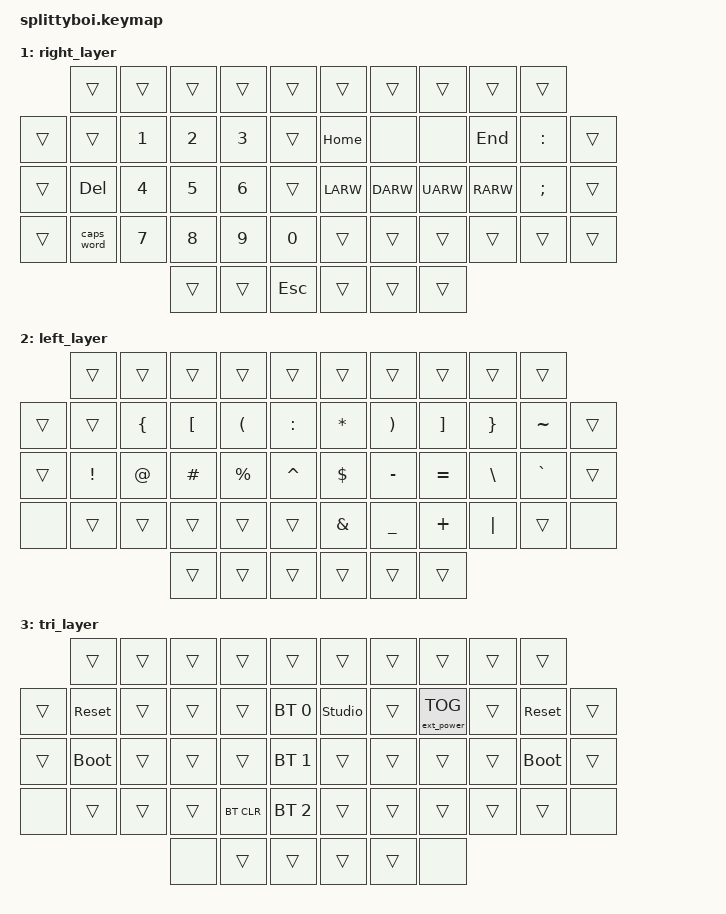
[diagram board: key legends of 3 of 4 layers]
// Copyright (c) 2022 The ZMK Contributors
// SPDX-License-Identifier: MIT

#include <behaviors.dtsi>
#include <dt-bindings/zmk/keys.h>
#include <dt-bindings/zmk/bt.h>
#include <dt-bindings/zmk/ext_power.h>

// Home row mods macro
#define HRML(k2,k3,k4) &ht LCTRL k2  &ht LALT k3  &ht LGUI k4
#define HRMR(k1,k2,k3) &ht RGUI k1  &ht RALT k2  &ht RCTRL k3

/ {
    behaviors {
        ht: hold_tap {
            label = "hold_tap";
            compatible = "zmk,behavior-hold-tap";
            #binding-cells = <2>;
            flavor = "tap-preferred";
            tapping-term-ms = <220>;
            quick-tap-ms = <150>;
            global-quick-tap;
            bindings = <&kp>, <&kp>;
        };    
    };

    macros {
        ZMK_MACRO(nvim_save,
            wait-ms = <10>;
            tap-ms = <20>;
            bindings = <&kp COLON  &kp W &kp ENTER>;
        )
    
        ZMK_MACRO(quit_nvim,
            wait-ms = <10>;
            tap-ms = <20>;
            bindings = <&kp COLON  &kp Q &kp ENTER>;
        )
        tmux_prefix: tmux_prefix {
            compatible = "zmk,behavior-macro";
            #binding-cells = <0>;
            bindings
                = <&macro_press &kp LCTRL>
                , <&macro_tap &kp A>
                , <&macro_release &kp LCTRL>
                ;
        };
    };

    conditional_layers {
        compatible = "zmk,conditional-layers";
        tri_layer {
            if-layers = <1 2>;
            then-layer = <3>;
        };
    };


    keymap {
        compatible = "zmk,keymap";
        default_layer {
            bindings = <
        //              ╭──────────┬──────────┬──────────┬──────────┬──────────╮   ╭──────────┬──────────┬──────────┬──────────┬──────────╮
        //              │  1       │  2       │  3       │  4       │     5    │   │  6       │  7       │  8       │  9       │   0      │
                            &kp N1   &kp N2     &kp N3       &kp N4     &kp N5      &kp N6  &kp N7      &kp N8   &kp N9     &kp N0 
        //   ╭──────────┼──────────┼──────────┼──────────┼──────────┼──────────┤   ├──────────┼──────────┼──────────┼──────────┼──────────┼──────────╮
        //   │          │  Q       │  W       │  E       │  R       │  T       │   │  Y       │  U       │  I       │  O       │  P       │          │
               &none       &kp Q      &kp W      &kp E      &kp R      &kp T          &kp Y      &kp U      &kp I      &kp O      &kp P     &none    
        //   ├──────────┼──────────┼──────────┼──────────┼──────────┼──────────┤   ├──────────┼──────────┼──────────┼──────────┼──────────┼──────────┤
        //   │  SHIFT   │  A       │  S       │  D       │  F       │  G       │   │  H       │  J       │  K       │  L       │ ' "      │  SHIFT   │
              &kp LSHFT   &kp A    HRML( S,         D,         F)     &kp G          &kp H      HRMR(J,        K,         L)     &kp SQT   &kp RSHFT
        //   ├──────────┼──────────┼──────────┼──────────┼──────────┼──────────┤   ├──────────┼──────────┼──────────┼──────────┼──────────┼──────────┤
        //   │          │  Z       │  X       │  C       │  V       │  B       │   │  N       │  M       │ , <      │ . >      │ / ?      │          │ 
               &none      &kp Z      &kp X      &kp C      &kp V      &kp B          &kp N      &kp M      &kp COMMA  &kp DOT    &kp FSLH   &none   
        //   ╰──────────┴──────────┴──────────┼──────────┼──────────┼──────────┤   ├──────────┼──────────┼──────────┼──────────┴──────────┴──────────╯
                                                &mo 2      &kp TAB   &kp ENTER      &kp BSPC    &none     &lt 1 SPACE  
        //                                    ╰──────────┴──────────┴──────────╯   ╰──────────┴──────────┴──────────╯
            >;
        };


        right_layer {
            bindings = <
        //           ╭──────────┬──────────┬──────────┬──────────┬──────────╮   ╭──────────┬──────────┬──────────┬──────────┬──────────╮
        //           │  0       │  1       │  2       │  3       │  4       │   │  5       │  6       │  7       │  8       │  9       │
                       &trans     &trans     &trans    &trans      &trans        &trans      &trans      &trans      &trans      &trans
        //╭──────────┼──────────┼──────────┼──────────┼──────────┼──────────┤   ├──────────┼──────────┼──────────┼──────────┼──────────┼──────────╮
        //│          │    Q     │  1       │  2       │  3       │          │   │ HOME     | none     | none     │ END      │  :       │          │
            &trans     &trans    &kp N1     &kp N2     &kp N3     &trans         &kp HOME   &none     &none       &kp END    &kp COLON   &trans  
        //├──────────┼──────────┼──────────┼──────────┼──────────┼──────────┤   ├──────────┼──────────┼──────────┼──────────┼──────────┼──────────┤
        //│  SHIFT   │ DELETE   │  4       │  5       │  6       │          │   │ LEFT     │ DOWN     │ UP       │ RIGHT    │  ;       │  SHIFT   │
           &trans     &kp DEL    &kp N4     &kp N5     &kp N6     &trans         &kp LARW   &kp DARW   &kp UARW    &kp RARW   &kp SEMI   &trans
        //├──────────┼──────────┼──────────┼──────────┼──────────┼──────────┤   ├──────────┼──────────┼──────────┼──────────┼──────────┼──────────┤
        //│          │ CAPS     │  7       │  8       │  9       │  0       │   │          │          │          │          │          │          │
            &trans    &caps_word  &kp N7     &kp N8     &kp N9     &kp N0         &trans     &trans     &trans     &trans     &trans      &trans   
        //╰──────────┴──────────┴──────────┴──────────┼──────────┼──────────┤   ├──────────┼──────────┼──────────┴──────────┴──────────┴──────────╯
                                               &trans   &trans      &kp ESC         &trans     &trans     &trans
        //                                 ╰──────────┴──────────┴──────────╯   ╰──────────┴──────────┴──────────╯
            >;
        };

        left_layer {
            bindings = <
        //           ╭──────────┬──────────┬──────────┬──────────┬──────────╮   ╭──────────┬──────────┬──────────┬──────────┬──────────╮
        //           │  0       │  1       │  2       │  3       │  4       │   │  5       │  6       │  7       │  8       │  9       │
                       &trans     &trans     &trans    &trans      &trans        &trans      &trans      &trans      &trans      &trans
        //╭──────────┼──────────┼──────────┼──────────┼──────────┼──────────┤   ├──────────┼──────────┼──────────┼──────────┼──────────┼──────────╮
        //│          │          │ {        │  [       │  (       │    :     │   │   *      │  )       │  ]       │  }       │  ~       │          │
            &trans    &trans     &kp LBRC   &kp LBKT   &kp LPAR   &kp COLON      &kp ASTRK &kp RPAR   &kp RBKT   &kp RBRC   &kp TILDE     &trans
        //├──────────┼──────────┼──────────┼──────────┼──────────┼──────────┤   ├──────────┼──────────┼──────────┼──────────┼──────────┼──────────╮
        //│  SHIFT   │  !       │  @       │  #       │   %      │    ^     │   │   $      │  -       │  =       │  \       │  `       │  SHIFT   │
           &trans     &kp EXCL   &kp AT     &kp HASH   &kp PRCNT   &kp CARET      &kp DLLR  &kp MINUS  &kp EQUAL  &kp BSLH   &kp GRAVE  &trans 
        //├──────────┼──────────┼──────────┼──────────┼──────────┼──────────┤   ├──────────┼──────────┼──────────┼──────────┼──────────┼──────────┤
        //│          │          │          │          │          │          │   │  &       │  _       │  +       │  │       │          │          │
            &none     &trans     &trans     &trans     &trans     &trans         &kp AMPS   &kp UNDER  &kp PLUS   &kp PIPE   &trans      &none   
        //╰──────────┴──────────┴──────────┴──────────┼──────────┼──────────┤   ├──────────┼──────────┼──────────┴──────────┴──────────┴──────────╯
                                              &trans      &trans     &trans         &trans     &trans     &trans
                   //                      ╰──────────┴──────────┴──────────╯   ╰──────────┴──────────┴──────────╯
            >;
        };


        tri_layer {
            bindings = <
        //           ╭──────────┬──────────┬──────────┬──────────┬──────────╮   ╭──────────┬──────────┬──────────┬──────────┬──────────╮
        //           │  0       │  1       │  2       │  3       │  4       │   │  5       │  6       │  7       │  8       │  9       │
                       &trans     &trans     &trans    &trans      &trans        &trans      &trans      &trans     &trans     &trans
        //╭──────────┼──────────┼──────────┼──────────┼──────────┼──────────┤   ├──────────┼──────────┼──────────┼──────────┼──────────┼──────────╮
        //           │ RESET    │          │          │          │PROFILE 0 │   │          │          │          │          │  RESET   │          │
            &trans     &sys_reset   &trans     &trans    &trans   &bt BT_SEL 0  &studio_unlock  &trans  &ext_power EP_TOG &trans  &sys_reset  &trans
        //╭──────────┼──────────┼──────────┼──────────┼──────────┼──────────┤   ├──────────┼──────────┼──────────┼──────────┼──────────┼──────────┤
        //│  SHIFT   │BOOTLOADER│          │          │          │PROFILE 1 │   │          │          │          │          │BOOTLOADER│  SHIFT   │
           &trans     &bootloader  &trans     &trans     &trans    &bt BT_SEL 1    &trans     &trans     &trans     &trans   &bootloader   &trans 
        //├──────────┼──────────┼──────────┼──────────┼──────────┼──────────┤   ├──────────┼──────────┼──────────┼──────────┼──────────┼──────────┤
        //│          │          │          │          │ CLEAR BT │PROFILE 2 │   │          │          │          │          │          │          │
            &none      &trans     &trans     &trans    &bt BT_CLR &bt BT_SEL 2    &trans     &trans     &trans     &trans     &trans       &none    
        //╰──────────┴──────────┴──────────┴──────────┼──────────┼──────────┤   ├──────────┼──────────┼──────────┴──────────┴──────────┴──────────╯
                                              &none      &trans      &trans          &trans     &trans     &none
        //                                 ╰──────────┴──────────┴──────────╯   ╰──────────┴──────────┴──────────╯
            >;
        };
        
        extra1 {
            status = "reserved";
        };
    };
};
